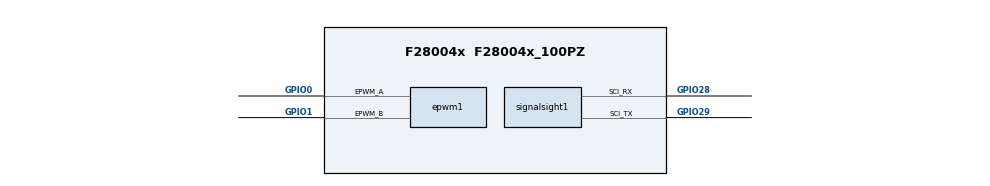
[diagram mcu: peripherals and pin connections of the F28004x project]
/**
 * @cliArgs --device "F28004x" --part "F28004x_100PZ" --package "F28004x_100PZ" --context "system" --product "C2000WARE@26.00.00.00"
 * @versions {"tool":"1.27.0+4565"}
 */

/**
 * Import the modules used in this configuration.
 */
const dma              = scripting.addModule("/driverlib/dma.js", {}, false);
const dma1             = dma.addInstance();
const dma2             = dma.addInstance();
const dma3             = dma.addInstance();
const epwm             = scripting.addModule("/driverlib/epwm.js", {}, false);
const epwm1            = epwm.addInstance();
const epwm2            = epwm.addInstance();
const epwm3            = epwm.addInstance();
const inputxbar        = scripting.addModule("/driverlib/inputxbar.js", {}, false);
const inputxbar1       = inputxbar.addInstance();
const inputxbar_input  = scripting.addModule("/driverlib/inputxbar_input.js");
const inputxbar_input1 = inputxbar_input.addInstance();
const inputxbar_input2 = inputxbar_input.addInstance();
const sync             = scripting.addModule("/driverlib/sync.js");
const signalsight      = scripting.addModule("/utilities/transfer/signalsight.js", {}, false);
const signalsight1     = signalsight.addInstance();

/**
 * Write custom configuration values to the imported modules.
 */
dma1.$name                = "myDMA0";
dma1.triggerSource        = "DMA_TRIGGER_EPWM1SOCA";
dma1.enableTriggers       = true;
dma1.databusWidthConfig   = "DMA_CFG_SIZE_32BIT";
dma1.burstSize            = 2;
dma1.transferSize         = 50;
dma1.continuousModeConfig = "DMA_CFG_CONTINUOUS_ENABLE";
dma1.srcBurstStep         = 1;
dma1.srcTransferStep      = 1;
dma1.destBurstStep        = 1;
dma1.destTransferStep     = -1;
dma1.srcWrapSize          = 100;
dma1.srcAddressVariable   = "0";
dma1.destAddressManual    = 0x4012;

dma2.$name                = "myDMA1";
dma2.enableTriggers       = true;
dma2.databusWidthConfig   = "DMA_CFG_SIZE_32BIT";
dma2.burstSize            = 2;
dma2.transferSize         = 50;
dma2.continuousModeConfig = "DMA_CFG_CONTINUOUS_ENABLE";
dma2.srcBurstStep         = 1;
dma2.srcTransferStep      = 1;
dma2.destBurstStep        = 1;
dma2.destTransferStep     = -1;
dma2.dmaBase              = "DMA_CH2_BASE";
dma2.triggerSource        = "DMA_TRIGGER_EPWM4SOCA";
dma2.srcWrapSize          = 100;
dma2.srcAddressVariable   = "0";
dma2.destAddressManual    = 0x4312;

dma3.$name                = "myDMA2";
dma3.enableTriggers       = true;
dma3.databusWidthConfig   = "DMA_CFG_SIZE_32BIT";
dma3.burstSize            = 2;
dma3.transferSize         = 50;
dma3.continuousModeConfig = "DMA_CFG_CONTINUOUS_ENABLE";
dma3.srcBurstStep         = 1;
dma3.srcTransferStep      = 1;
dma3.destBurstStep        = 1;
dma3.destTransferStep     = -1;
dma3.dmaBase              = "DMA_CH3_BASE";
dma3.triggerSource        = "DMA_TRIGGER_EPWM7SOCA";
dma3.srcWrapSize          = 100;
dma3.srcAddressVariable   = "0";
dma3.destAddressManual    = 0x4612;

epwm1.$name                                                    = "myEPWM1";
epwm1.epwmTimebase_hsClockDiv                                  = "EPWM_HSCLOCK_DIVIDER_1";
epwm1.epwmActionQualifier_EPWM_AQ_OUTPUT_B_ON_TIMEBASE_ZERO    = "EPWM_AQ_OUTPUT_HIGH";
epwm1.epwmTimebase_syncOutPulseMode                            = "EPWM_SYNC_OUT_PULSE_ON_COUNTER_ZERO";
epwm1.epwmDeadband_polarityFED                                 = "EPWM_DB_POLARITY_ACTIVE_LOW";
epwm1.epwmDeadband_enableRED                                   = true;
epwm1.epwmDeadband_enableFED                                   = true;
epwm1.epwmDeadband_delayRED                                    = 240;
epwm1.epwmDeadband_delayFED                                    = 240;
epwm1.epwmCounterCompare_cmpA                                  = 1000;
epwm1.epwmCounterCompare_cmpB                                  = 500;
epwm1.epwmEventTrigger_EPWM_SOC_A_triggerEnable                = true;
epwm1.epwmEventTrigger_EPWM_SOC_A_triggerEventPrescalar        = "2";
epwm1.epwmTimebase_period                                      = 1999;
epwm1.epwmTimebase_counterMode                                 = "EPWM_COUNTER_MODE_UP";
epwm1.epwmActionQualifier_EPWM_AQ_OUTPUT_A_shadowMode          = true;
epwm1.epwmActionQualifier_EPWM_AQ_OUTPUT_A_ON_TIMEBASE_UP_CMPA = "EPWM_AQ_OUTPUT_TOGGLE";
epwm1.epwmActionQualifier_EPWM_AQ_OUTPUT_A_ON_TIMEBASE_UP_CMPB = "EPWM_AQ_OUTPUT_TOGGLE";
epwm1.epwmActionQualifier_EPWM_AQ_OUTPUT_B_shadowMode          = true;
epwm1.epwmActionQualifier_EPWM_AQ_OUTPUT_B_ON_TIMEBASE_UP_CMPA = "EPWM_AQ_OUTPUT_TOGGLE";
epwm1.epwmActionQualifier_EPWM_AQ_OUTPUT_B_ON_TIMEBASE_UP_CMPB = "EPWM_AQ_OUTPUT_TOGGLE";
epwm1.epwmEventTrigger_enableInterrupt                         = true;
epwm1.epwmEventTrigger_EPWM_SOC_A_triggerSource                = "EPWM_SOC_TBCTR_ZERO";
epwm1.epwm.$assign                                             = "EPWM1";
epwm1.epwm.epwm_aPin.$assign                                   = "GPIO0";
epwm1.epwm.epwm_bPin.$assign                                   = "GPIO1";

epwm2.$name                                                    = "myEPWM4";
epwm2.epwmTimebase_hsClockDiv                                  = "EPWM_HSCLOCK_DIVIDER_1";
epwm2.epwmCounterCompare_cmpA                                  = 1000;
epwm2.epwmCounterCompare_cmpB                                  = 500;
epwm2.epwmActionQualifier_EPWM_AQ_OUTPUT_B_ON_TIMEBASE_ZERO    = "EPWM_AQ_OUTPUT_HIGH";
epwm2.epwmDeadband_polarityFED                                 = "EPWM_DB_POLARITY_ACTIVE_LOW";
epwm2.epwmDeadband_enableRED                                   = true;
epwm2.epwmDeadband_delayRED                                    = 240;
epwm2.epwmDeadband_enableFED                                   = true;
epwm2.epwmDeadband_delayFED                                    = 240;
epwm2.epwmEventTrigger_enableInterrupt                         = true;
epwm2.epwmTimebase_period                                      = 1999;
epwm2.epwmTimebase_counterMode                                 = "EPWM_COUNTER_MODE_UP";
epwm2.copyUse                                                  = true;
epwm2.copyFrom                                                 = "myEPWM1";
epwm2.epwmTimebase_syncOutPulseMode                            = "EPWM_SYNC_OUT_PULSE_ON_COUNTER_ZERO";
epwm2.epwmActionQualifier_EPWM_AQ_OUTPUT_A_shadowMode          = true;
epwm2.epwmActionQualifier_EPWM_AQ_OUTPUT_A_ON_TIMEBASE_UP_CMPA = "EPWM_AQ_OUTPUT_TOGGLE";
epwm2.epwmActionQualifier_EPWM_AQ_OUTPUT_A_ON_TIMEBASE_UP_CMPB = "EPWM_AQ_OUTPUT_TOGGLE";
epwm2.epwmActionQualifier_EPWM_AQ_OUTPUT_B_shadowMode          = true;
epwm2.epwmActionQualifier_EPWM_AQ_OUTPUT_B_ON_TIMEBASE_UP_CMPA = "EPWM_AQ_OUTPUT_TOGGLE";
epwm2.epwmActionQualifier_EPWM_AQ_OUTPUT_B_ON_TIMEBASE_UP_CMPB = "EPWM_AQ_OUTPUT_TOGGLE";
epwm2.epwmEventTrigger_interruptSource                         = "EPWM_INT_TBCTR_ZERO_OR_PERIOD";
epwm2.epwmEventTrigger_interruptEventCount                     = "2";
epwm2.epwmTimebase_phaseEnable                                 = true;
epwm2.epwmTimebase_phaseShift                                  = 667;
epwm2.epwmEventTrigger_EPWM_SOC_A_triggerEnable                = true;
epwm2.epwmEventTrigger_EPWM_SOC_A_triggerSource                = "EPWM_SOC_TBCTR_ZERO";

epwm3.$name                                                    = "myEPWM7";
epwm3.epwmTimebase_hsClockDiv                                  = "EPWM_HSCLOCK_DIVIDER_1";
epwm3.epwmCounterCompare_cmpA                                  = 1000;
epwm3.epwmCounterCompare_cmpB                                  = 500;
epwm3.epwmActionQualifier_EPWM_AQ_OUTPUT_B_ON_TIMEBASE_ZERO    = "EPWM_AQ_OUTPUT_HIGH";
epwm3.epwmDeadband_polarityFED                                 = "EPWM_DB_POLARITY_ACTIVE_LOW";
epwm3.epwmDeadband_enableRED                                   = true;
epwm3.epwmDeadband_delayRED                                    = 240;
epwm3.epwmDeadband_enableFED                                   = true;
epwm3.epwmDeadband_delayFED                                    = 240;
epwm3.epwmEventTrigger_enableInterrupt                         = true;
epwm3.epwmTimebase_period                                      = 1999;
epwm3.epwmTimebase_counterMode                                 = "EPWM_COUNTER_MODE_UP";
epwm3.copyUse                                                  = true;
epwm3.copyFrom                                                 = "myEPWM1";
epwm3.epwmTimebase_syncOutPulseMode                            = "EPWM_SYNC_OUT_PULSE_ON_COUNTER_ZERO";
epwm3.epwmActionQualifier_EPWM_AQ_OUTPUT_A_shadowMode          = true;
epwm3.epwmActionQualifier_EPWM_AQ_OUTPUT_A_ON_TIMEBASE_UP_CMPA = "EPWM_AQ_OUTPUT_TOGGLE";
epwm3.epwmActionQualifier_EPWM_AQ_OUTPUT_A_ON_TIMEBASE_UP_CMPB = "EPWM_AQ_OUTPUT_TOGGLE";
epwm3.epwmActionQualifier_EPWM_AQ_OUTPUT_B_shadowMode          = true;
epwm3.epwmActionQualifier_EPWM_AQ_OUTPUT_B_ON_TIMEBASE_UP_CMPA = "EPWM_AQ_OUTPUT_TOGGLE";
epwm3.epwmActionQualifier_EPWM_AQ_OUTPUT_B_ON_TIMEBASE_UP_CMPB = "EPWM_AQ_OUTPUT_TOGGLE";
epwm3.epwmEventTrigger_interruptSource                         = "EPWM_INT_TBCTR_ZERO_OR_PERIOD";
epwm3.epwmEventTrigger_interruptEventCount                     = "2";
epwm3.epwmTimebase_phaseEnable                                 = true;
epwm3.epwmTimebase_phaseShift                                  = 1333;
epwm3.epwmEventTrigger_EPWM_SOC_A_triggerEnable                = true;
epwm3.epwmEventTrigger_EPWM_SOC_A_triggerSource                = "EPWM_SOC_TBCTR_ZERO";

inputxbar1.$name = "myINPUTXBAR5";

inputxbar_input1.$name          = "myINPUTXBARINPUT0";
inputxbar_input1.inputxbarInput = "XBAR_INPUT5";
inputxbar_input1.inputxbarGpio  = "GPIO56";

inputxbar_input2.$name          = "myINPUTXBARINPUT1";
inputxbar_input2.inputxbarInput = "XBAR_INPUT6";
inputxbar_input2.inputxbarGpio  = "GPIO56";

sync.epwm4SyncInSource = "SYSCTL_SYNC_IN_SRC_EXTSYNCIN1";
sync.epwm7SyncInSource = "SYSCTL_SYNC_IN_SRC_EXTSYNCIN1";

signalsight1.$name                                            = "myMCUSignalSight0";
signalsight1.bufferSize                                       = 50;
signalsight1.exporter.comsLinkModule.loopback                 = scripting.forceWrite(false);
signalsight1.exporter.comsLinkModule.wordLenght               = scripting.forceWrite("8");
signalsight1.exporter.comsLinkModule.stop                     = scripting.forceWrite("ONE");
signalsight1.exporter.comsLinkModule.parity                   = scripting.forceWrite("SCI_CONFIG_PAR_NONE");
signalsight1.exporter.comsLinkModule.useFifo                  = scripting.forceWrite(true);
signalsight1.exporter.comsLinkModule.txFifo                   = scripting.forceWrite("SCI_FIFO_TX0");
signalsight1.exporter.comsLinkModule.useCase                  = scripting.forceWrite("ALL");
signalsight1.exporter.comsLinkModule.sci.$assign              = "SCIA";
signalsight1.exporter.comsLinkModule.sci.sci_rxPin.$assign    = "GPIO28";
signalsight1.exporter.comsLinkModule.sci.sci_txPin.$assign    = "GPIO29";
signalsight1.exporter.comsLinkModule.rxQual.$name             = "myGPIOQUAL0";
signalsight1.exporter.comsLinkModule.txQual.$name             = "myGPIOQUAL1";
signalsight1.exporter.comsLinkModule.sciTXInt.enableInterrupt = scripting.forceWrite(false);
signalsight1.hash.$name                                       = "myHashTable0";
signalsight1.hash.hashElements.create(9);
signalsight1.hash.hashElements[0].$name                       = "sopwm_m";
signalsight1.hash.hashElements[1].$name                       = "sopwm_theta";
signalsight1.hash.hashElements[2].$name                       = "sopwm_angle1";
signalsight1.hash.hashElements[3].$name                       = "sopwm_angle2";
signalsight1.hash.hashElements[4].$name                       = "sopwm_angle3";
signalsight1.hash.hashElements[5].$name                       = "sopwm_angle4";
signalsight1.hash.hashElements[6].$name                       = "sopwm_angle5";
signalsight1.hash.hashElements[7].$name                       = "sopwm_angle6";
signalsight1.hash.hashElements[8].$name                       = "sopwm_angle7";

/**
 * Pinmux solution for unlocked pins/peripherals. This ensures that minor changes to the automatic solver in a future
 * version of the tool will not impact the pinmux you originally saw.  These lines can be completely deleted in order to
 * re-solve from scratch.
 */
epwm2.epwm.$suggestSolution           = "EPWM3";
epwm2.epwm.epwm_aPin.$suggestSolution = "GPIO4";
epwm2.epwm.epwm_bPin.$suggestSolution = "GPIO5";
epwm3.epwm.$suggestSolution           = "EPWM2";
epwm3.epwm.epwm_aPin.$suggestSolution = "GPIO2";
epwm3.epwm.epwm_bPin.$suggestSolution = "GPIO3";
